# AVR128DA32S device description
Architecture: AVR8X; Family: AVR
Registers are 8-bit, read-write, reset 0x0 unless marked. A register's access mark holds for its fields unless they carry their own. Offsets are from the block's base; [hi:lo] are bit positions.

## CLKCTRL — Clock controller
Instances: CLKCTRL 0x0060
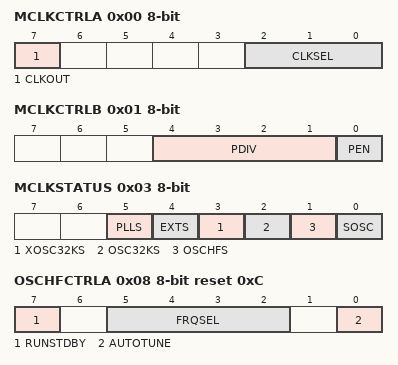
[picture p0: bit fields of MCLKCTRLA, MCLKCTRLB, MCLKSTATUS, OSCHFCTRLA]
0x00 MCLKCTRLA — MCLK Control A
  [7] CLKOUT — System clock out
  [2:0] CLKSEL — Clock select
    0=OSCHF (Internal high-frequency oscillator); 1=OSC32K (Internal 32.768 kHz oscillator); 2=XOSC32K (32.768 kHz crystal oscillator); 3=EXTCLK (External clock)
0x01 MCLKCTRLB — MCLK Control B
  [4:1] PDIV — Prescaler division
    0=2X; 1=4X; 2=8X; 3=16X; 4=32X; 5=64X; 8=6X; 9=10X; 10=12X; 11=24X; 12=48X
  [0] PEN — Prescaler enable
0x02 MCLKLOCK reset not defined
  [0] LOCKEN — lock ebable
0x03 MCLKSTATUS
  [5] PLLS — PLL oscillator status
  [4] EXTS — External Clock status
  [3] XOSC32KS — 32.768 kHz Crystal Oscillator status
  [2] OSC32KS — 32KHz oscillator status
  [1] OSCHFS — High frequency oscillator status
  [0] SOSC — System Oscillator changing
0x08 OSCHFCTRLA reset 0xC — OSCHF Control A
  [7] RUNSTDBY — Run standby
  [5:2] FRQSEL — Frequency select
    0=1M (1 MHz system clock); 1=2M (2 MHz system clock); 2=3M (3 MHz system clock); 3=4M (4 MHz system clock (default)); 5=8M (8 MHz system clock); 6=12M (12 MHz system clock); 7=16M (16 MHz system clock); 8=20M (20 MHz system clock); 9=24M (24 MHz system clock)
  [0] AUTOTUNE
0x09 OSCHFTUNE reset not defined
  [7:0] TUNE
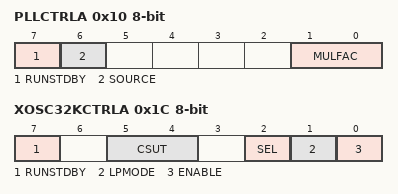
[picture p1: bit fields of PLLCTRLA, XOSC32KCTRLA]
0x10 PLLCTRLA reset not defined — PLL Control A
  [7] RUNSTDBY — Run standby
  [6] SOURCE
  [1:0] MULFAC — Multiplication factor
    0=DISABLE (PLL is disabled); 1=2x (2 x multiplication factor); 2=3x (3 x multiplication factor)
0x18 OSC32KCTRLA — OSC32K Control A
  [7] RUNSTDBY — Run standby
0x1C XOSC32KCTRLA — XOSC32K Control A
  [7] RUNSTDBY — Run standby
  [5:4] CSUT — Crystal startup time
    0=1K (1k cycles); 1=16K (16k cycles); 2=32K (32k cycles); 3=64K (64k cycles)
  [2] SEL — Select
  [1] LPMODE — Low power mode
  [0] ENABLE

## CPU
Instances: CPU 0x0030
0x04 CCP — Configuration Change Protection
  [7:0] CCP — CCP signature
    157=SPM (SPM Instruction Protection); 216=IOREG (IO Register Protection)
0x0B RAMPZ — Extended Z-pointer Register
  [0] RAMPZ — Extended Z-Pointer Address bits
0x0D SP 16-bit reset 0x7FFF — Stack Pointer
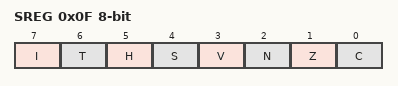
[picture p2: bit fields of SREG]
0x0F SREG — Status Register
  [7] I — Global Interrupt Enable Flag
  [6] T — Transfer Bit
  [5] H — Half Carry Flag
  [4] S — N Exclusive Or V Flag
  [3] V — Two's Complement Overflow Flag
  [2] N — Negative Flag
  [1] Z — Zero Flag
  [0] C — Carry Flag

## CPUINT — Interrupt Controller
Instances: CPUINT 0x0110
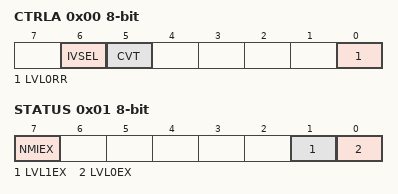
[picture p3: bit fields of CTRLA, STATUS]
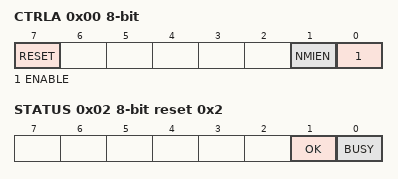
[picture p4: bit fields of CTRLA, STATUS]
0x00 CTRLA — Control A
  [6] IVSEL — Interrupt Vector Select
  [5] CVT — Compact Vector Table
  [0] LVL0RR — Round-robin Scheduling Enable
0x01 STATUS ro
  [7] NMIEX — Non-maskable Interrupt Executing
  [1] LVL1EX — Level 1 Interrupt Executing
  [0] LVL0EX — Level 0 Interrupt Executing
0x02 LVL0PRI — Interrupt Level 0 Priority
  [7:0] LVL0PRI — Interrupt Level Priority
0x03 LVL1VEC — Interrupt Level 1 Priority Vector
  [7:0] LVL1VEC — Interrupt Vector with High Priority

## CRCSCAN
Instances: CRCSCAN 0x0120
0x00 CTRLA — Control A
  [7] RESET — Reset CRC scan
  [1] NMIEN — Enable NMI Trigger
  [0] ENABLE — Enable CRC scan
0x01 CTRLB — Control B
  [1:0] SRC — CRC Source
    0=FLASH (CRC on entire flash); 1=BOOTAPP (CRC on boot and appl section of flash); 2=BOOT (CRC on boot section of flash)
0x02 STATUS ro reset 0x2
  [1] OK — CRC Ok
  [0] BUSY — CRC Busy

## DAC — Digital to Analog Converter
Instances: DAC0 0x06A0
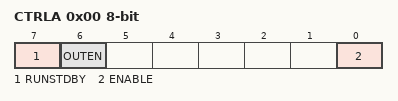
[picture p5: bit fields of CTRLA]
0x00 CTRLA — Control Register A
  [7] RUNSTDBY — Run in Standby Mode
  [6] OUTEN — Output Buffer Enable
  [0] ENABLE — DAC Enable
0x02 DATA 16-bit reset not defined
  [15:6] DATA

## FUSE — Fuses
Instances: FUSE 0x1050
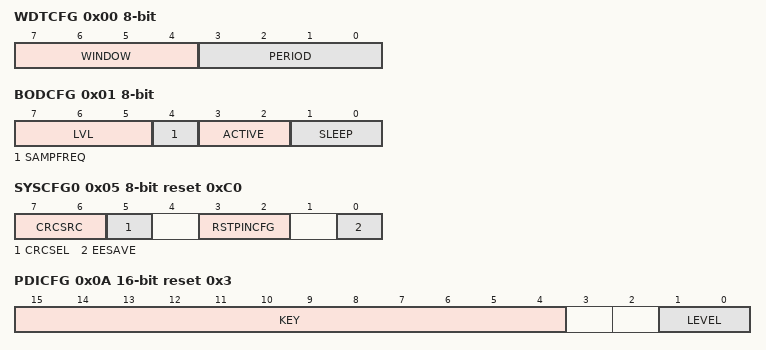
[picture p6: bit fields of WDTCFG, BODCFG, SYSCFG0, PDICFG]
0x00 WDTCFG — Watchdog Configuration
  [7:4] WINDOW — Watchdog Window Timeout Period
    0=OFF (Window mode off); 1=8CLK (8 cycles (8ms)); 2=16CLK (16 cycles (16ms)); 3=32CLK (32 cycles (32ms)); 4=64CLK (64 cycles (64ms)); 5=128CLK (128 cycles (0.128s)); 6=256CLK (256 cycles (0.256s)); 7=512CLK (512 cycles (0.512s)); 8=1KCLK (1K cycles (1.0s)); 9=2KCLK (2K cycles (2.0s)); 10=4KCLK (4K cycles (4.0s)); 11=8KCLK (8K cycles (8.0s))
  [3:0] PERIOD — Watchdog Timeout Period
    0=OFF (Watch-Dog timer Off); 1=8CLK (8 cycles (8ms)); 2=16CLK (16 cycles (16ms)); 3=32CLK (32 cycles (32ms)); 4=64CLK (64 cycles (64ms)); 5=128CLK (128 cycles (0.128s)); 6=256CLK (256 cycles (0.256s)); 7=512CLK (512 cycles (0.512s)); 8=1KCLK (1K cycles (1.0s)); 9=2KCLK (2K cycles (2.0s)); 10=4KCLK (4K cycles (4.0s)); 11=8KCLK (8K cycles (8.0s))
0x01 BODCFG — BOD Configuration
  [7:5] LVL — BOD Level
    0=BODLEVEL0 (1.9V); 1=BODLEVEL1 (2.45V); 2=BODLEVEL2 (2.7V); 3=BODLEVEL3 (2.85V)
  [4] SAMPFREQ — BOD Sample Frequency
    0=128Hz (Sample frequency is 128 Hz); 1=32Hz (Sample frequency is 32 Hz)
  [3:2] ACTIVE — BOD Operation in Active Mode
    0=DISABLE (BOD disabled); 1=ENABLE (BOD enabled in continuous mode); 2=SAMPLE (BOD enabled in sampled mode); 3=ENABLEWAIT (BOD enabled in continuous mode. Execution is halted at wake-up until BOD is running.)
  [1:0] SLEEP — BOD Operation in Sleep Mode
    0=DISABLE (BOD disabled); 1=ENABLE (BOD enabled in continuous mode); 2=SAMPLE (BOD enabled in sampled mode)
0x02 OSCCFG — Oscillator Configuration
  [2:0] CLKSEL — Frequency Select
    0=OSCHF (1-32MHz internal oscillator); 1=OSC32K (32.768kHz internal oscillator)
0x05 SYSCFG0 reset 0xC0 — System Configuration 0
  [7:6] CRCSRC — CRC Source
    0=FLASH (CRC of full Flash (boot, application code and application data)); 1=BOOT (CRC of boot section); 2=BOOTAPP (CRC of application code and boot sections); 3=NOCRC
  [5] CRCSEL — CRC Select
    0=CRC16 (Enable CRC16); 1=CRC32 (Enable CRC32)
  [3:2] RSTPINCFG — Reset Pin Configuration
    0=GPIO (GPIO mode); 2=RST (Reset mode)
  [0] EESAVE — EEPROM Save
0x06 SYSCFG1 — System Configuration 1
  [2:0] SUT — Startup Time
    0=0MS; 1=1MS; 2=2MS; 3=4MS; 4=8MS; 5=16MS; 6=32MS; 7=64MS
0x07 CODESIZE — Code Section Size
0x08 BOOTSIZE — Boot Section Size
0x0A PDICFG 16-bit reset 0x3 — Programming and Debugging Interface Configuration
  [15:4] KEY — NVM Protection Activation Key
    0=NOTACT (Not Active); 0xB45=NVMACT (NVM Protection Active)
  [1:0] LEVEL — Protection Level
    2=NVMACCDIS (NVM Access through UPDI disabled); 3=BASIC (UPDI and UPDI pins working normally)
